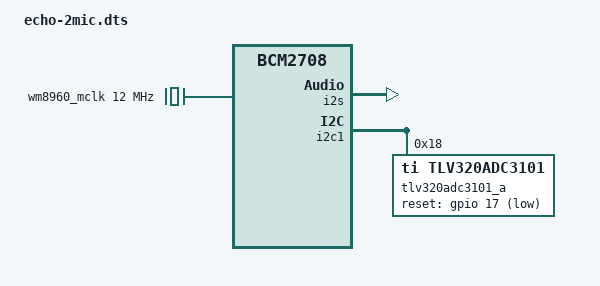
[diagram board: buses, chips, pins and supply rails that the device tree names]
/dts-v1/;
/plugin/;

/ {
    compatible = "brcm,bcm2708";

    fragment@0 {
      target = <&i2s>;
      __overlay__ {
        status = "okay";
      };
    };
    fragment@1 {
      target-path="/";
      __overlay__ {
        wm8960_mclk: wm8960_mclk {
          compatible = "fixed-clock";
          #clock-cells = <0>;
          clock-frequency = <12000000>;
        };

      };
    };
    fragment@2 {
      target = <&i2c1>;
      __overlay__ {
        #address-cells = <1>;
        #size-cells = <0>;
        status = "okay";

        tlv320adc3101_a: tlv320adc3101@18 {
          compatible = "ti,tlv320adc3101";
          reg = <0x18>;
          #sound-dai-cells = <0>;
          status = "okay";
          
          clocks = <&clocks 38>;
          clock-names = "mclk";
          assigned-clocks = <&clocks 38>;
          assigned-clock-rates = <12000000>;

          pinctrl-names = "default";
          pinctrl-0 = <&gpclk0_pin &tlv320adc3101_reset>;

          reset-gpios = <&gpio 17 1>;
          gpio-controller;
          #gpio-cells = <2>;
          ti,dmdin-gpio1 = <0>;
          ti,dmdin-gpio2 = <0>;
          ti,micbias1-vg = <2>;
          ti,micbias2-vg = <2>;
          ti,dout3state;
          dai-tdm-slot-width = <32>;
        };
      };
    };


    fragment@3 {
      target = <&sound>;
      slave_overlay: __overlay__ {
        compatible = "simple-audio-card";
        simple-audio-card,format = "i2s";
        simple-audio-card,name = "echo-2mic-voicecard"; 
        status = "okay";
        simple-audio-card,cpu {
            sound-dai = <&i2s>;
        };
        dailink0_slave: simple-audio-card,codec {
          sound-dai = <&tlv320adc3101_a>;
          //bitclock-master = <&tlv320adc3101_a>;
          //frame-master = <&tlv320adc3101_a>;
          bitclock-inversion;
          clocks = <&wm8960_mclk>;
          clock-names = "mclk";
        };
      };
    };
    fragment@4 {
      target = <&gpio>;
      __overlay__ {
        gpclk0_pin: gpclk0_pin {
          brcm,pins = <4>;
          brcm,function = <4>;
        };
        tlv320adc3101_reset: tlv320adc3101_reset {
          brcm,pins = <17>;
          brcm,function = <1>;
          brcm,pull = <1>;
        };
      };
    };
 
    __overrides__ {
      alsaname = <&slave_overlay>,"simple-audio-card,name";
      compatible = <&tlv320adc3101_a>,"compatible";
      master = <0>,"=2!3";
    };
};

